VERSION ""

NS_ :

BS_:

BU_:

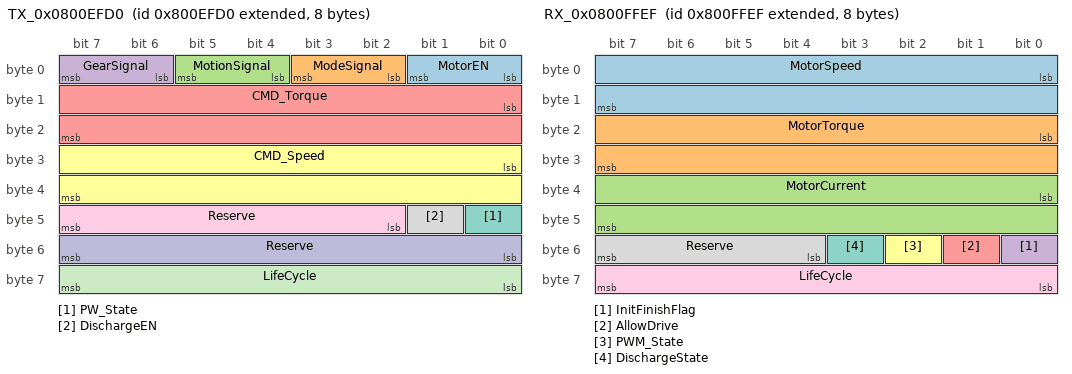
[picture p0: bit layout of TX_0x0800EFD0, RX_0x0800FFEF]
BO_ 2281762768 TX_0x0800EFD0: 8 Vector__XXX
 SG_ MotorEN : 0|2@1+ (1,0) [0|0] "" Vector__XXX
 SG_ ModeSignal : 2|2@1+ (1,0) [0|0] "" Vector__XXX
 SG_ MotionSignal : 4|2@1+ (1,0) [0|0] "" Vector__XXX
 SG_ GearSignal : 6|2@1+ (1,0) [0|0] "" Vector__XXX
 SG_ CMD_Torque : 8|16@1+ (0.1,0) [0|1000] "Nm" Vector__XXX
 SG_ CMD_Speed : 24|16@1+ (1,-15000) [0|30000] "rpm" Vector__XXX
 SG_ PW_State : 40|1@1+ (1,0) [0|0] "" Vector__XXX
 SG_ DischargeEN : 41|1@1+ (1,0) [0|0] "" Vector__XXX
 SG_ Reserve : 42|6@1+ (1,0) [0|0] "" Vector__XXX
 SG_ Reserve : 48|8@1+ (1,0) [0|0] "" Vector__XXX
 SG_ LifeCycle : 56|8@1+ (1,0) [0|255] "" Vector__XXX

BO_ 2281766895 RX_0x0800FFEF: 8 Vector__XXX
 SG_ MotorSpeed : 0|16@1+ (1,-15000) [0|30000] "rpm" Vector__XXX
 SG_ MotorTorque : 16|16@1+ (0.1,0) [0|1000] "Nm" Vector__XXX
 SG_ MotorCurrent : 32|16@1+ (0.1,0) [0|1000] "A" Vector__XXX
 SG_ InitFinishFlag : 48|1@1+ (1,0) [0|0] "" Vector__XXX
 SG_ AllowDrive : 49|1@1+ (1,0) [0|0] "" Vector__XXX
 SG_ PWM_State : 50|1@1+ (1,0) [0|0] "" Vector__XXX
 SG_ DischargeState : 51|1@1+ (1,0) [0|0] "" Vector__XXX
 SG_ Reserve : 52|4@1+ (1,0) [0|0] "" Vector__XXX
 SG_ LifeCycle : 56|8@1+ (1,0) [0|0] "" Vector__XXX

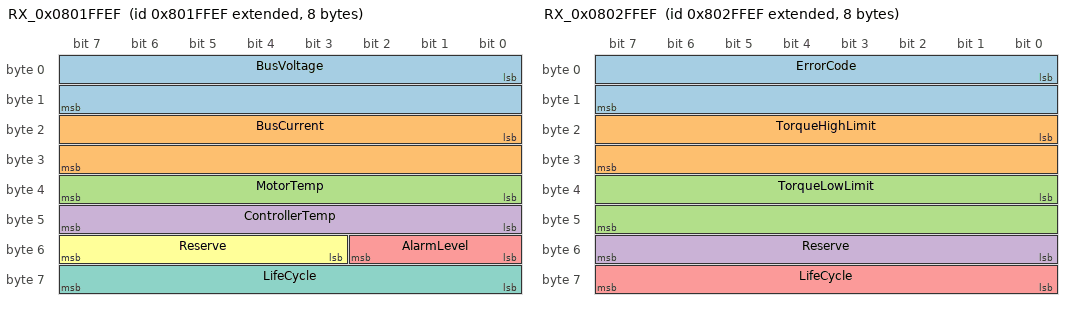
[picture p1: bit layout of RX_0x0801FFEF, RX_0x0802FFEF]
BO_ 2281832431 RX_0x0801FFEF: 8 Vector__XXX
 SG_ BusVoltage : 0|16@1+ (0.1,0) [0|1000] "V" Vector__XXX
 SG_ BusCurrent : 16|16@1+ (0.1,-1000) [0|2000] "A" Vector__XXX
 SG_ MotorTemp : 32|8@1+ (1,-40) [0|255] "degrees Celsius" Vector__XXX
 SG_ ControllerTemp : 40|8@1+ (1,-40) [0|255] "degrees Celsius" Vector__XXX
 SG_ AlarmLevel : 48|3@1+ (1,0) [0|0] "" Vector__XXX
 SG_ Reserve : 51|5@1+ (1,0) [0|0] "" Vector__XXX
 SG_ LifeCycle : 56|8@1+ (1,0) [0|255] "" Vector__XXX

BO_ 2281897967 RX_0x0802FFEF: 8 Vector__XXX
 SG_ ErrorCode : 0|16@1+ (1,0) [0|65535] "" Vector__XXX
 SG_ TorqueHighLimit : 16|16@1+ (1,0) [0|5000] "Nm" Vector__XXX
 SG_ TorqueLowLimit : 32|16@1+ (1,-5000) [0|5000] "Nm" Vector__XXX
 SG_ Reserve : 48|8@1+ (1,0) [0|0] "" Vector__XXX
 SG_ LifeCycle : 56|8@1+ (1,0) [0|255] "" Vector__XXX
